VERSION ""

NS_ :

BS_:

BU_: Vector__XXX BSR CAA CAA00 CAA01 CGW CSR FCM FRD MAV

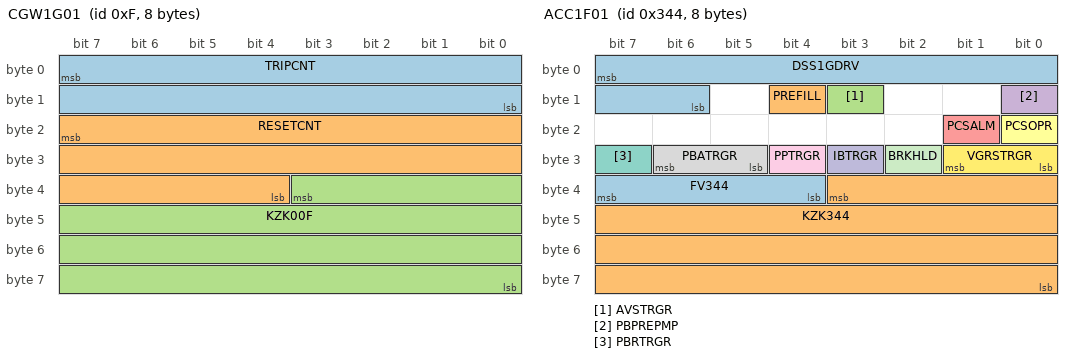
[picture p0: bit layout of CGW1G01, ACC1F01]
BO_ 15 CGW1G01: 8 Vector__XXX
  SG_ TRIPCNT   : 7|16@0+ (1,0) [0|0] "" Vector__XXX
  SG_ RESETCNT   : 23|20@0+ (1,0) [0|0] "" Vector__XXX
  SG_ KZK00F   : 35|28@0+ (1,0) [0|0] "" Vector__XXX

BO_ 836 ACC1F01: 8 FCM
  SG_ DSS1GDRV: 7|10@0- (0.1,0) [0|0] "m/s^2" CGW
  SG_ PREFILL: 12|1@0+ (1,0) [0|0] "" CGW
  SG_ AVSTRGR: 11|1@0+ (1,0) [0|0] "" CGW
  SG_ PBPREPMP: 8|1@0+ (1,0) [0|0] "" CGW
  SG_ PCSALM: 17|1@0+ (1,0) [0|0] "" CGW
  SG_ PCSOPR: 16|1@0+ (1,0) [0|0] "" CGW
  SG_ PBRTRGR: 31|1@0+ (1,0) [0|0] "" CGW
  SG_ PBATRGR: 30|2@0+ (1,0) [0|0] "" CGW
  SG_ PPTRGR: 28|1@0+ (1,0) [0|0] "" CGW
  SG_ IBTRGR: 27|1@0+ (1,0) [0|0] "" CGW
  SG_ BRKHLD: 26|1@0+ (1,0) [0|0] "" CGW
  SG_ VGRSTRGR: 25|2@0+ (1,0) [0|0] "" CGW
  SG_ FV344: 39|4@0+ (1,0) [0|0] "" CGW
  SG_ KZK344: 35|28@0+ (1,0) [0|0] "" CGW

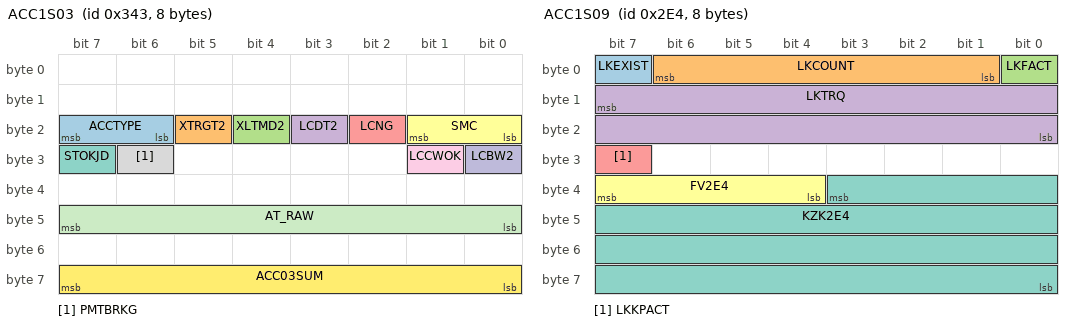
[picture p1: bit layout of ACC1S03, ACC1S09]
BO_ 835 ACC1S03: 8 FCM
  SG_ ACCTYPE: 23|2@0+ (1,0) [0|0] "" CGW
  SG_ XTRGT2: 21|1@0+ (1,0) [0|0] "" CGW
  SG_ XLTMD2: 20|1@0+ (1,0) [0|0] "" CGW
  SG_ LCDT2: 19|1@0+ (1,0) [0|0] "" CGW
  SG_ LCNG: 18|1@0+ (1,0) [0|0] "" CGW
  SG_ SMC: 17|2@0+ (1,0) [0|0] "" CGW
  SG_ STOKJD: 31|1@0+ (1,0) [0|0] "" CGW
  SG_ PMTBRKG: 30|1@0+ (1,0) [0|0] "" CGW
  SG_ LCCWOK: 25|1@0+ (1,0) [0|0] "" CGW
  SG_ LCBW2: 24|1@0+ (1,0) [0|0] "" CGW
  SG_ AT_RAW: 47|8@0- (0.05,0) [0|0] "m/s^2" CGW
  SG_ ACC03SUM: 63|8@0+ (1,0) [0|0] "" CGW

BO_ 740 ACC1S09: 8 FCM
  SG_ LKEXIST: 7|1@0+ (1,0) [0|0] "" CGW
  SG_ LKCOUNT: 6|6@0+ (1,0) [0|0] "" CGW
  SG_ LKFACT: 0|1@0+ (1,0) [0|0] "" CGW
  SG_ LKTRQ: 15|16@0- (0.01,0) [0|0] "Nm" CGW
  SG_ LKKPACT: 31|1@0+ (1,0) [0|0] "" CGW
  SG_ FV2E4: 39|4@0+ (1,0) [0|0] "" CGW
  SG_ KZK2E4: 35|28@0+ (1,0) [0|0] "" CGW

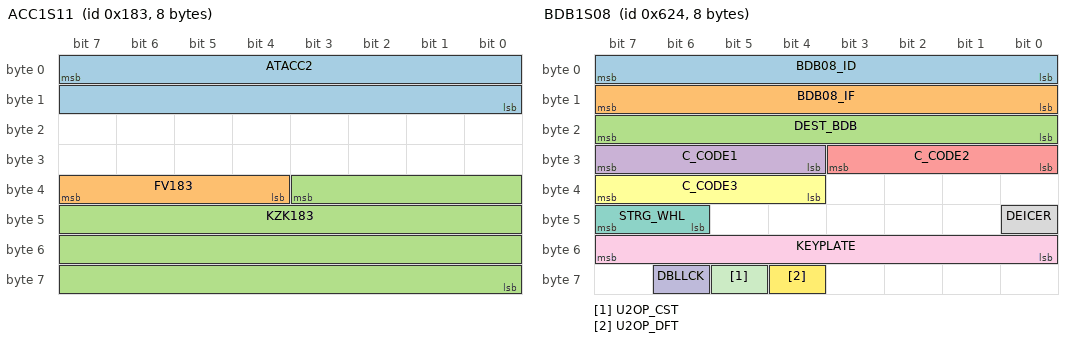
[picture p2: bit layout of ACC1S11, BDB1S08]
BO_ 387 ACC1S11: 8 FCM
  SG_ ATACC2: 7|16@0- (0.001,0) [0|0] "m/s^2" CGW
  SG_ FV183: 39|4@0+ (1,0) [0|0] "" CGW
  SG_ KZK183: 35|28@0+ (1,0) [0|0] "" CGW

BO_ 1572 BDB1S08: 8 CGW
  SG_ BDB08_ID: 7|8@0+ (1,0) [0|0] "" FCM
  SG_ BDB08_IF: 15|8@0+ (1,0) [0|0] "" FCM
  SG_ DEST_BDB: 23|8@0+ (1,0) [0|0] "" BSR,CAA,CAA00,CAA01,CSR,FCM,MAV
  SG_ C_CODE1: 31|4@0+ (1,0) [0|0] "" BSR,CAA,CAA00,CAA01,FCM,MAV
  SG_ C_CODE2: 27|4@0+ (1,0) [0|0] "" BSR,CAA,CAA00,CAA01,CSR,FCM,MAV
  SG_ C_CODE3: 39|4@0+ (1,0) [0|0] "" BSR,CAA,CAA00,CAA01,CSR,FCM,MAV
  SG_ STRG_WHL: 47|2@0+ (1,0) [0|0] "" CAA,CAA00,CAA01,CSR,FCM,MAV
  SG_ DEICER: 40|1@0+ (1,0) [0|0] "" Vector__XXX
  SG_ KEYPLATE: 55|8@0+ (1,0) [0|0] "" Vector__XXX
  SG_ DBLLCK: 62|1@0+ (1,0) [0|0] "" Vector__XXX
  SG_ U2OP_CST: 61|1@0+ (1,0) [0|0] "" Vector__XXX
  SG_ U2OP_DFT: 60|1@0+ (1,0) [0|0] "" Vector__XXX

BO_ 1014 BSR1S01: 8 BSR
  SG_ BSD_STAT: 7|3@0+ (1,0) [0|0] "" CGW
  SG_ RCTA_DIR: 4|3@0+ (1,0) [0|0] "" CAA,CAA00,CAA01,CGW,CSR,MAV
  SG_ BS4LDR: 1|1@0+ (1,0) [0|0] "" CGW,FCM
  SG_ BS4LDL: 0|1@0+ (1,0) [0|0] "" CGW,FCM
  SG_ BSD_SW: 15|1@0+ (1,0) [0|0] "" CGW
  SG_ RCTA_EQ: 14|1@0+ (1,0) [0|0] "" CGW,CSR
  SG_ RCTA_VOL: 13|2@0+ (1,0) [0|0] "" CGW,CSR
  SG_ RCTADISP: 11|1@0+ (1,0) [0|0] "" CAA,CAA00,CAA01,CGW,MAV
  SG_ CV4LDR: 10|1@0+ (1,0) [0|0] "" CGW,FCM
  SG_ RCTA_SW: 9|1@0+ (1,0) [0|0] "" CGW
  SG_ CV4LDL: 8|1@0+ (1,0) [0|0] "" CGW,FCM
  SG_ BSD_BUZ: 23|1@0+ (1,0) [0|0] "" CGW,CSR
  SG_ BSD_ILCR: 22|1@0+ (1,0) [0|0] "" CGW
  SG_ BSD_ILV: 21|3@0+ (1,0) [0|0] "" CGW
  SG_ BSD_ITCR: 18|1@0+ (1,0) [0|0] "" CGW
  SG_ BSD_ITV: 17|2@0+ (1,0) [0|0] "" CGW
  SG_ BSD_OMIL: 27|2@0+ (1,0) [0|0] "" CGW
  SG_ BSD_OMIR: 25|2@0+ (1,0) [0|0] "" CGW
  SG_ RCTASTAT: 39|3@0+ (1,0) [0|0] "" CGW
  SG_ BUZSTAT: 36|2@0+ (1,0) [0|0] "" CGW
  SG_ CAAICM: 34|1@0+ (1,0) [0|0] "" CGW
  SG_ RCTALAMP: 33|2@0+ (1,0) [0|0] "" CGW
  SG_ BSD_TTR: 47|1@0+ (1,0) [0|0] "" CGW
  SG_ BSDINDI: 46|1@0+ (1,0) [0|0] "" CGW
  SG_ RCTA_TTR: 45|1@0+ (1,0) [0|0] "" CGW
  SG_ BSD_SWR: 44|1@0+ (1,0) [0|0] "" CGW
  SG_ RCTA_SWR: 43|1@0+ (1,0) [0|0] "" CGW
  SG_ RCTA_BUZ: 42|1@0+ (1,0) [0|0] "" CGW,CSR
  SG_ RCTA_BCR: 41|1@0+ (1,0) [0|0] "" CGW

BO_ 870 DS11D71: 7 FCM
  SG_ TGT_ETTC: 7|6@0+ (0.1,0) [0|0] "s" CGW
  SG_ XREQPBR: 1|1@0+ (1,0) [0|0] "" CGW
  SG_ XREQPREF: 0|1@0+ (1,0) [0|0] "" CGW
  SG_ TGT_OBJT: 15|4@0+ (1,0) [0|0] "" CGW
  SG_ XREQALM: 11|2@0+ (1,0) [0|0] "" CGW
  SG_ XREQPBA: 9|2@0+ (1,0) [0|0] "" CGW
  SG_ TGT_VGAP: 23|9@0- (0.14,-21.7) [0|0] "m/s" CGW
  SG_ TGT_DIST: 30|7@0+ (0.79,0) [0|0] "m" CGW
  SG_ TGT_NUMB: 39|5@0+ (1,1) [0|0] "" CGW
  SG_ XREQABK: 34|1@0+ (1,0) [0|0] "" CGW
  SG_ XREQFPB: 33|1@0+ (1,0) [0|0] "" CGW
  SG_ XREQPB: 32|1@0+ (1,0) [0|0] "" CGW
  SG_ TGT_POSX: 47|5@0- (0.32,0) [0|0] "m" CGW
  SG_ XREQPSB: 42|1@0+ (1,0) [0|0] "" CGW
  SG_ XPCSRDY: 41|1@0+ (1,0) [0|0] "" CGW
  SG_ TGT_TTCT: 40|1@0+ (1,0) [0|0] "" CGW
  SG_ ALLPCSF: 55|1@0+ (1,0) [0|0] "" CGW
  SG_ TGT_LSPD: 54|7@0- (0.2,0) [0|0] "m/s" CGW

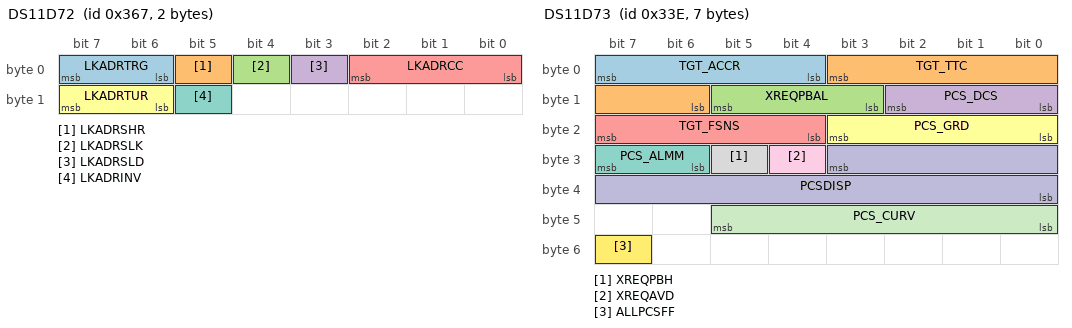
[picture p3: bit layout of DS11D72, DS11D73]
BO_ 871 DS11D72: 2 FCM
  SG_ LKADRTRG: 7|2@0+ (1,0) [0|0] "" CGW
  SG_ LKADRSHR: 5|1@0+ (1,0) [0|0] "" CGW
  SG_ LKADRSLK: 4|1@0+ (1,0) [0|0] "" CGW
  SG_ LKADRSLD: 3|1@0+ (1,0) [0|0] "" CGW
  SG_ LKADRCC: 2|3@0+ (1,0) [0|0] "" CGW
  SG_ LKADRTUR: 15|2@0+ (1,0) [0|0] "" CGW
  SG_ LKADRINV: 13|1@0+ (1,0) [0|0] "" CGW

BO_ 830 DS11D73: 7 FCM
  SG_ TGT_ACCR: 7|4@0- (1,0) [0|0] "m/s2" CGW
  SG_ TGT_TTC: 3|6@0+ (0.1,0) [0|0] "s" CGW
  SG_ XREQPBAL: 13|3@0+ (1,0) [0|0] "" CGW
  SG_ PCS_DCS: 10|3@0+ (1,0) [0|0] "" CGW
  SG_ TGT_FSNS: 23|4@0+ (1,0) [0|0] "" CGW
  SG_ PCS_GRD: 19|4@0+ (1,0) [0|0] "" CGW
  SG_ PCS_ALMM: 31|2@0+ (1,0) [0|0] "" CGW
  SG_ XREQPBH: 29|1@0+ (1,0) [0|0] "" CGW
  SG_ XREQAVD: 28|1@0+ (1,0) [0|0] "" CGW
  SG_ PCSDISP: 27|12@0+ (1,0) [0|0] "" CGW
  SG_ PCS_CURV: 45|6@0- (200,0) [0|0] "m" CGW
  SG_ ALLPCSFF: 55|1@0+ (1,0) [0|0] "" CGW

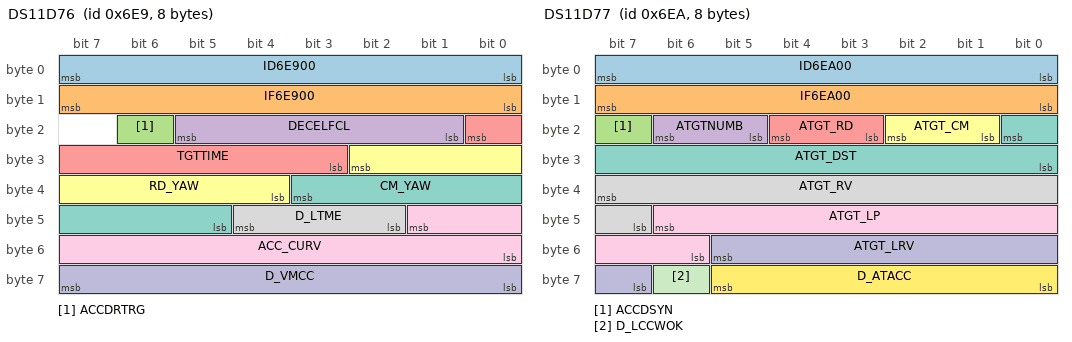
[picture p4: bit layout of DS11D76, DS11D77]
BO_ 1769 DS11D76: 8 FCM
  SG_ ID6E900: 7|8@0+ (1,0) [0|0] "" CGW
  SG_ IF6E900: 15|8@0+ (1,0) [0|0] "" CGW
  SG_ ACCDRTRG: 22|1@0+ (1,0) [0|0] "" CGW
  SG_ DECELFCL: 21|5@0+ (0.2,0) [0|0] "m/s^2" CGW
  SG_ TGTTIME: 16|6@0+ (0.2,0) [0|0] "s" CGW
  SG_ RD_YAW: 26|7@0- (0.1,0) [0|0] "deg" CGW
  SG_ CM_YAW: 35|7@0- (0.1,0) [0|0] "deg" CGW
  SG_ D_LTME: 44|3@0+ (1,0) [0|0] "" CGW
  SG_ ACC_CURV: 41|10@0- (50,0) [0|0] "m" CGW
  SG_ D_VMCC: 63|8@0+ (1,0) [0|0] "km/h" CGW

BO_ 1770 DS11D77: 8 FCM
  SG_ ID6EA00: 7|8@0+ (1,0) [0|0] "" CGW
  SG_ IF6EA00: 15|8@0+ (1,0) [0|0] "" CGW
  SG_ ACCDSYN: 23|1@0+ (1,0) [0|0] "" CGW
  SG_ ATGTNUMB: 22|2@0+ (1,0) [0|0] "" CGW
  SG_ ATGT_RD: 20|2@0+ (1,0) [0|0] "" CGW
  SG_ ATGT_CM: 18|2@0+ (1,0) [0|0] "" CGW
  SG_ ATGT_DST: 16|9@0+ (1,0) [0|0] "m" CGW
  SG_ ATGT_RV: 39|9@0- (0.3,0) [0|0] "m/s" CGW
  SG_ ATGT_LP: 46|9@0- (0.2,0) [0|0] "m" CGW
  SG_ ATGT_LRV: 53|7@0- (0.2,0) [0|0] "m/s" CGW
  SG_ D_LCCWOK: 62|1@0+ (1,0) [0|0] "" CGW
  SG_ D_ATACC: 61|6@0- (0.2,0) [0|0] "m/s^2" CGW

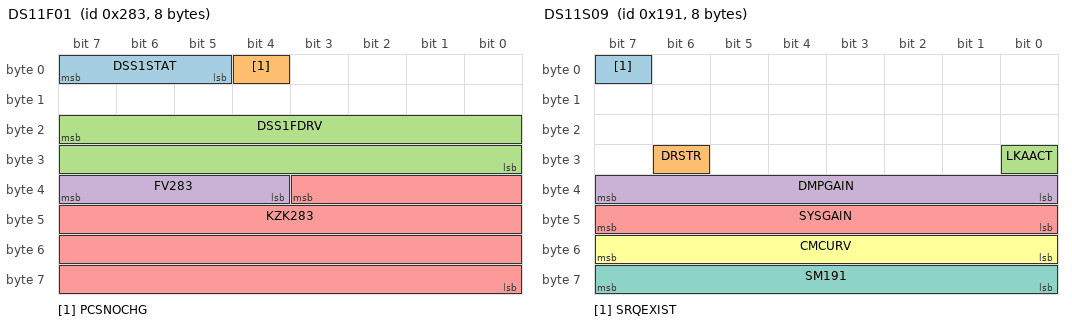
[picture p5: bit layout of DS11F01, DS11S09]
BO_ 643 DS11F01: 8 FCM
  SG_ DSS1STAT: 7|3@0+ (1,0) [0|0] "" CGW
  SG_ PCSNOCHG: 4|1@0+ (1,0) [0|0] "" CGW
  SG_ DSS1FDRV: 23|16@0- (2,0) [0|0] "N" CGW
  SG_ FV283: 39|4@0+ (1,0) [0|0] "" CGW
  SG_ KZK283: 35|28@0+ (1,0) [0|0] "" CGW

BO_ 401 DS11S09: 8 FCM
  SG_ SRQEXIST: 7|1@0+ (1,0) [0|0] "" CGW
  SG_ DRSTR: 30|1@0+ (1,0) [0|0] "" CGW
  SG_ LKAACT: 24|1@0+ (1,0) [0|0] "" CGW
  SG_ DMPGAIN: 39|8@0+ (0.01,0) [0|0] "" CGW
  SG_ SYSGAIN: 47|8@0+ (0.01,0) [0|0] "" CGW
  SG_ CMCURV: 55|8@0- (0.0001,0) [0|0] "1/m" CGW
  SG_ SM191: 63|8@0+ (1,0) [0|0] "" CGW

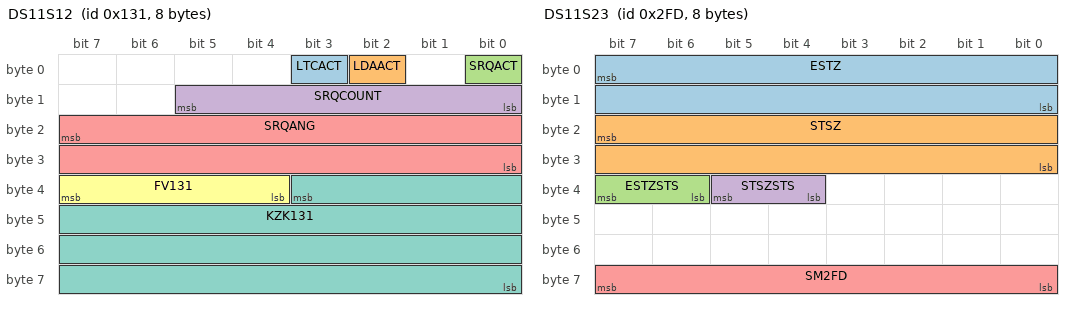
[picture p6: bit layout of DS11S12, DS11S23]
BO_ 305 DS11S12: 8 FCM
  SG_ LTCACT: 3|1@0+ (1,0) [0|0] "" CGW
  SG_ LDAACT: 2|1@0+ (1,0) [0|0] "" CGW
  SG_ SRQACT: 0|1@0+ (1,0) [0|0] "" CGW
  SG_ SRQCOUNT: 13|6@0+ (1,0) [0|0] "" CGW
  SG_ SRQANG: 23|16@0- (0.001,0) [0|0] "rad" CGW
  SG_ FV131: 39|4@0+ (1,0) [0|0] "" CGW
  SG_ KZK131: 35|28@0+ (1,0) [0|0] "" CGW

BO_ 765 DS11S23: 8 FCM
  SG_ ESTZ: 7|16@0- (0.001,0) [0|0] "rad" CGW
  SG_ STSZ: 23|16@0- (0.001,0) [0|0] "rad" CGW
  SG_ ESTZSTS: 39|2@0+ (1,0) [0|0] "" CGW
  SG_ STSZSTS: 37|2@0+ (1,0) [0|0] "" CGW
  SG_ SM2FD: 63|8@0+ (1,0) [0|0] "" CGW

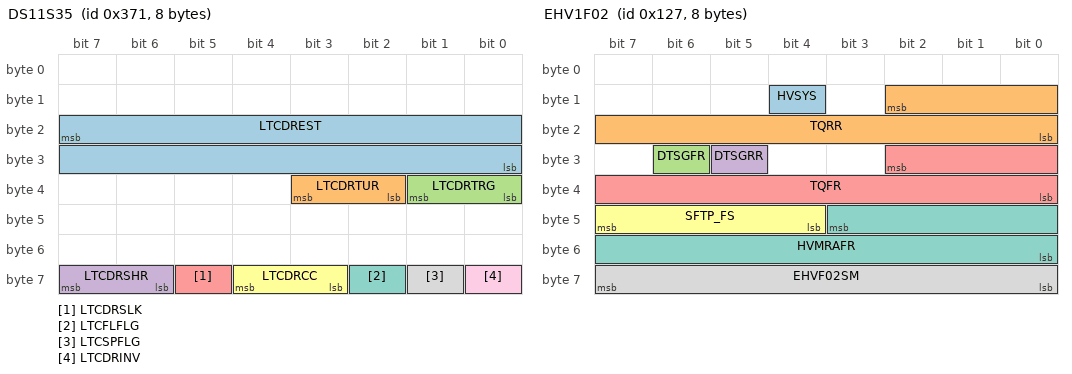
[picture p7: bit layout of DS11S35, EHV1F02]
BO_ 881 DS11S35: 8 FCM
  SG_ LTCDREST: 23|16@0- (0.001,0) [0|0] "rad" CGW
  SG_ LTCDRTUR: 35|2@0+ (1,0) [0|0] "" CGW
  SG_ LTCDRTRG: 33|2@0+ (1,0) [0|0] "" CGW
  SG_ LTCDRSHR: 63|2@0+ (1,0) [0|0] "" CGW
  SG_ LTCDRSLK: 61|1@0+ (1,0) [0|0] "" CGW
  SG_ LTCDRCC: 60|2@0+ (1,0) [0|0] "" CGW
  SG_ LTCFLFLG: 58|1@0+ (1,0) [0|0] "" CGW
  SG_ LTCSPFLG: 57|1@0+ (1,0) [0|0] "" CGW
  SG_ LTCDRINV: 56|1@0+ (1,0) [0|0] "" CGW

BO_ 1041 DS12F02: 8 FCM
  SG_ PCSINDI: 7|2@0+ (1,0) [0|0] "" CGW
  SG_ PCSWM: 5|2@0+ (1,0) [0|0] "" CGW
  SG_ PCSFCT: 3|1@0+ (1,0) [0|0] "" CGW
  SG_ PCSTUCT: 2|1@0+ (1,0) [0|0] "" CGW
  SG_ DS1LCCK: 1|2@0+ (1,0) [0|0] "" CGW
  SG_ PBTUCT: 14|1@0+ (1,0) [0|0] "" CGW
  SG_ PCSEXIST: 13|1@0+ (1,0) [0|0] "" CGW
  SG_ PCSWDUCT: 11|1@0+ (1,0) [0|0] "" CGW
  SG_ PCSMTBZ2: 27|4@0+ (1,0) [0|0] "" CGW
  SG_ PCSDSRF: 36|1@0+ (1,0) [0|0] "" CGW
  SG_ PCSTEMP: 35|1@0+ (1,0) [0|0] "" CGW
  SG_ PCSDUST: 34|1@0+ (1,0) [0|0] "" CGW
  SG_ PCSLCCK: 33|2@0+ (1,0) [0|0] "" CGW
  SG_ PCTEMP2: 42|1@0+ (1,0) [0|0] "" CGW
  SG_ PCSDUST2: 41|1@0+ (1,0) [0|0] "" CGW
  SG_ PCSOFFS: 40|1@0+ (1,0) [0|0] "" CGW
  SG_ PCSWDS: 55|2@0+ (1,0) [0|0] "" CGW
  SG_ FRDADJ: 53|3@0+ (1,0) [0|0] "" CGW
  SG_ TSS_TS: 49|1@0+ (1,0) [0|0] "" CGW

BO_ 1042 DS12F03: 8 FCM
  SG_ LKAINDI: 7|2@0+ (1,0) [0|0] "" CGW
  SG_ LKAWLSL: 5|2@0+ (1,0) [0|0] "" CGW
  SG_ LKAWLSR: 3|2@0+ (1,0) [0|0] "" CGW
  SG_ LKAHS: 1|2@0+ (1,0) [0|0] "" CGW
  SG_ LKAFCT: 15|1@0+ (1,0) [0|0] "" CGW
  SG_ LKATUCT: 14|1@0+ (1,0) [0|0] "" CGW
  SG_ LKACAMT: 13|1@0+ (1,0) [0|0] "" CGW
  SG_ LKACB: 12|1@0+ (1,0) [0|0] "" CGW
  SG_ LDWEXIST: 10|1@0+ (1,0) [0|0] "" CGW
  SG_ LKAHFCT: 9|2@0+ (1,0) [0|0] "" CGW
  SG_ LKASPCND: 23|3@0+ (1,0) [0|0] "" CGW
  SG_ LKAMDCS: 20|2@0+ (1,0) [0|0] "" CGW
  SG_ LKAWTCS: 18|2@0+ (1,0) [0|0] "" CGW
  SG_ LKASAUT: 16|1@0+ (1,0) [0|0] "" CGW
  SG_ LKAMDT: 31|2@0+ (1,0) [0|0] "" CGW
  SG_ LTCCNFLV: 29|2@0+ (1,0) [0|0] "" CGW
  SG_ FLWMD2: 39|2@0+ (1,0) [0|0] "" CGW
  SG_ LDOFINDI: 37|1@0+ (1,0) [0|0] "" CGW
  SG_ LTCEXST2: 36|1@0+ (1,0) [0|0] "" CGW
  SG_ LDWBZ: 32|1@0+ (1,0) [0|0] "" CGW
  SG_ LDAFCVB: 47|1@0+ (1,0) [0|0] "" CGW
  SG_ SWSSENSD: 45|2@0+ (1,0) [0|0] "" CGW
  SG_ SWSSWD: 43|1@0+ (1,0) [0|0] "" CGW
  SG_ LDACD: 42|3@0+ (1,0) [0|0] "" CGW
  SG_ SWSRAD: 55|2@0+ (1,0) [0|0] "" CGW
  SG_ SWSBUZ: 50|2@0+ (1,0) [0|0] "" CGW
  SG_ LKAEXIST: 48|1@0+ (1,0) [0|0] "" CGW
  SG_ LKACTCD: 60|1@0+ (1,0) [0|0] "" CGW
  SG_ LDAWRNC: 59|1@0+ (1,0) [0|0] "" CGW
  SG_ SCEXIST: 57|1@0+ (1,0) [0|0] "" CGW
  SG_ VIBEXIST: 56|1@0+ (1,0) [0|0] "" CGW

BO_ 295 EHV1F02: 8 CGW
  SG_ HVSYS: 12|1@0+ (1,0) [0|0] "" CSR
  SG_ TQRR: 10|11@0- (8,0) [0|0] "Nm" Vector__XXX
  SG_ DTSGFR: 30|1@0+ (1,0) [0|0] "" Vector__XXX
  SG_ DTSGRR: 29|1@0+ (1,0) [0|0] "" Vector__XXX
  SG_ TQFR: 26|11@0- (8,0) [0|0] "Nm" Vector__XXX
  SG_ SFTP_FS: 47|4@0+ (1,0) [0|0] "" CSR
  SG_ HVMRAFR: 43|12@0+ (0.3515625,0) [0|0] "deg" Vector__XXX
  SG_ EHVF02SM: 63|8@0+ (1,0) [0|0] "" CSR

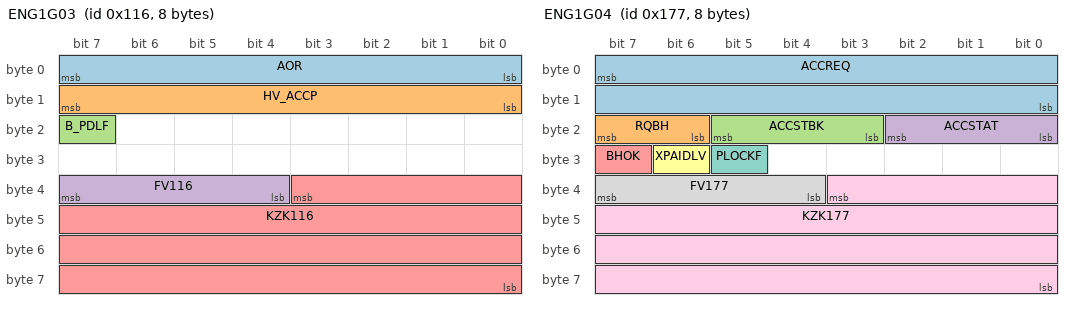
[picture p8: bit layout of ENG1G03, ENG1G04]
BO_ 278 ENG1G03: 8 CGW
  SG_ AOR: 7|8@0+ (0.5,0) [0|0] "%" Vector__XXX
  SG_ HV_ACCP: 15|8@0+ (0.5,0) [0|0] "%" CSR,FCM
  SG_ B_PDLF: 23|1@0+ (1,0) [0|0] "" FCM
  SG_ FV116: 39|4@0+ (1,0) [0|0] "" FCM
  SG_ KZK116: 35|28@0+ (1,0) [0|0] "" FCM

BO_ 375 ENG1G04: 8 CGW
  SG_ ACCREQ: 7|16@0- (0.0009765625,0) [0|0] "m/s^2" Vector__XXX
  SG_ RQBH: 23|2@0+ (1,0) [0|0] "" Vector__XXX
  SG_ ACCSTBK: 21|3@0+ (1,0) [0|0] "" Vector__XXX
  SG_ ACCSTAT: 18|3@0+ (1,0) [0|0] "" Vector__XXX
  SG_ BHOK: 31|1@0+ (1,0) [0|0] "" Vector__XXX
  SG_ XPAIDLV: 30|1@0+ (1,0) [0|0] "" CSR,FCM
  SG_ PLOCKF: 29|1@0+ (1,0) [0|0] "" Vector__XXX
  SG_ FV177: 39|4@0+ (1,0) [0|0] "" Vector__XXX
  SG_ KZK177: 35|28@0+ (1,0) [0|0] "" Vector__XXX

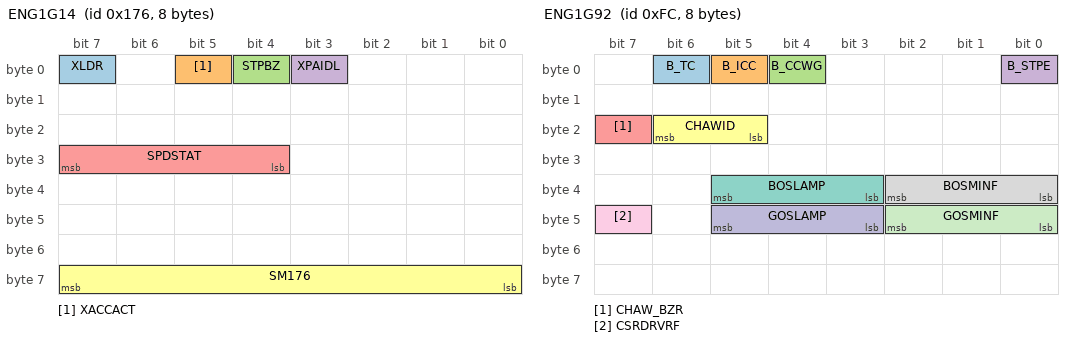
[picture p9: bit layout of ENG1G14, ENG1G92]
BO_ 374 ENG1G14: 8 CGW
  SG_ XLDR: 7|1@0+ (1,0) [0|0] "" FCM
  SG_ XACCACT: 5|1@0+ (1,0) [0|0] "" FCM
  SG_ STPBZ: 4|1@0+ (1,0) [0|0] "" FCM
  SG_ XPAIDL: 3|1@0+ (1,0) [0|0] "" FCM
  SG_ SPDSTAT: 31|4@0+ (1,0) [0|0] "�|" FCM
  SG_ SM176: 63|8@0+ (1,0) [0|0] "" FCM

BO_ 252 ENG1G92: 8 CGW
  SG_ B_TC: 6|1@0+ (1,0) [0|0] "" Vector__XXX
  SG_ B_ICC: 5|1@0+ (1,0) [0|0] "" Vector__XXX
  SG_ B_CCWG: 4|1@0+ (1,0) [0|0] "" Vector__XXX
  SG_ B_STPE: 0|1@0+ (1,0) [0|0] "" Vector__XXX
  SG_ CHAW_BZR: 23|1@0+ (1,0) [0|0] "" Vector__XXX
  SG_ CHAWID: 22|2@0+ (1,0) [0|0] "" Vector__XXX
  SG_ BOSLAMP: 37|3@0+ (1,0) [0|0] "" Vector__XXX
  SG_ BOSMINF: 34|3@0+ (1,0) [0|0] "" Vector__XXX
  SG_ CSRDRVRF: 47|1@0+ (1,0) [0|0] "" CSR
  SG_ GOSLAMP: 45|3@0+ (1,0) [0|0] "" FCM
  SG_ GOSMINF: 42|3@0+ (1,0) [0|0] "" FCM

BO_ 921 ENG1S95: 8 CGW
  SG_ ACCBZR: 7|3@0+ (1,0) [0|0] "" Vector__XXX
  SG_ B_SPU2: 4|1@0+ (1,0) [0|0] "" Vector__XXX
  SG_ ACASID1: 3|4@0+ (1,0) [0|0] "" Vector__XXX
  SG_ ACASID2: 15|8@0+ (1,0) [0|0] "" Vector__XXX
  SG_ RACMSDSP: 23|2@0+ (1,0) [0|0] "" Vector__XXX
  SG_ RACACOPR: 21|1@0+ (1,0) [0|0] "" Vector__XXX
  SG_ RACONDSP: 20|1@0+ (1,0) [0|0] "" Vector__XXX
  SG_ ASLBZR: 19|2@0+ (1,0) [0|0] "" Vector__XXX
  SG_ ACCOVSPD: 17|2@0+ (1,0) [0|0] "" Vector__XXX
  SG_ B_LSP2: 31|8@0+ (1,0) [0|0] "km/h�Emph" Vector__XXX
  SG_ B_ASLSP2: 39|8@0+ (1,0) [0|0] "km/h�Emph" Vector__XXX
  SG_ CACCTRN: 47|1@0+ (1,0) [0|0] "" Vector__XXX
  SG_ CACCINF: 46|1@0+ (1,0) [0|0] "" Vector__XXX
  SG_ CACCFR2: 45|1@0+ (1,0) [0|0] "" Vector__XXX
  SG_ CACCFR1: 44|1@0+ (1,0) [0|0] "" Vector__XXX
  SG_ CACCFLD: 43|1@0+ (1,0) [0|0] "" Vector__XXX
  SG_ CACCCM3: 42|1@0+ (1,0) [0|0] "" Vector__XXX
  SG_ CACCCM2: 41|1@0+ (1,0) [0|0] "" Vector__XXX
  SG_ CACCCM1: 40|1@0+ (1,0) [0|0] "" Vector__XXX
  SG_ ASLRNG: 55|1@0+ (1,0) [0|0] "" FCM
  SG_ RACCSTM2: 52|1@0+ (1,0) [0|0] "" Vector__XXX
  SG_ RACCSTM1: 51|2@0+ (1,0) [0|0] "" Vector__XXX
  SG_ RACEQPD: 49|1@0+ (1,0) [0|0] "" Vector__XXX
  SG_ RACID: 48|1@0+ (1,0) [0|0] "" Vector__XXX
  SG_ RACSPDOP: 63|8@0+ (1,0) [0|0] "km/h�Emph" Vector__XXX

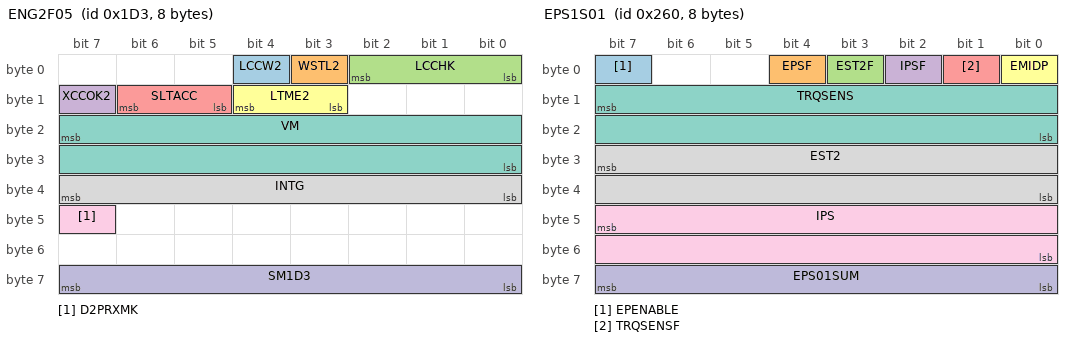
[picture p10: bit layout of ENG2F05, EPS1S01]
BO_ 467 ENG2F05: 8 CGW
  SG_ LCCW2: 4|1@0+ (1,0) [0|0] "" FCM
  SG_ WSTL2: 3|1@0+ (1,0) [0|0] "" FCM
  SG_ LCCHK: 2|3@0+ (1,0) [0|0] "" FCM
  SG_ XCCOK2: 15|1@0+ (1,0) [0|0] "" FCM
  SG_ SLTACC: 14|2@0+ (1,0) [0|0] "" FCM
  SG_ LTME2: 12|2@0+ (1,0) [0|0] "" FCM
  SG_ VM: 23|16@0+ (0.00390625,0) [0|0] "km/h" FCM
  SG_ INTG: 39|8@0- (0.04,0) [0|0] "m/s^2" FCM
  SG_ D2PRXMK: 47|1@0+ (1,0) [0|0] "" Vector__XXX
  SG_ SM1D3: 63|8@0+ (1,0) [0|0] "" FCM

BO_ 608 EPS1S01: 8 CGW
  SG_ EPENABLE: 7|1@0+ (1,0) [0|0] "" Vector__XXX
  SG_ EPSF: 4|1@0+ (1,0) [0|0] "" Vector__XXX
  SG_ EST2F: 3|1@0+ (1,0) [0|0] "" FCM
  SG_ IPSF: 2|1@0+ (1,0) [0|0] "" FCM
  SG_ TRQSENSF: 1|1@0+ (1,0) [0|0] "" FCM
  SG_ EMIDP: 0|1@0+ (1,0) [0|0] "" Vector__XXX
  SG_ TRQSENS: 15|16@0- (0.01,0) [0|0] "Nm" FCM
  SG_ EST2: 31|16@0- (0.001,0) [0|0] "rad" FCM
  SG_ IPS: 47|16@0- (0.01,0) [0|0] "A" FCM
  SG_ EPS01SUM: 63|8@0+ (1,0) [0|0] "" FCM

BO_ 610 EPS1S02: 8 CGW
  SG_ EPSFAIL: 7|1@0+ (1,0) [0|0] "" Vector__XXX
  SG_ EPSSPD: 6|1@0+ (1,0) [0|0] "" Vector__XXX
  SG_ EPSFCM: 5|1@0+ (1,0) [0|0] "" Vector__XXX
  SG_ EPSSTS0: 2|1@0+ (1,0) [0|0] "" Vector__XXX
  SG_ EPSACT: 1|1@0+ (1,0) [0|0] "" Vector__XXX
  SG_ EPSSYS: 0|1@0+ (1,0) [0|0] "" Vector__XXX
  SG_ EPSFANG: 15|1@0+ (1,0) [0|0] "" FCM
  SG_ EPSBKUP2: 14|1@0+ (1,0) [0|0] "" FCM
  SG_ EPSACT3: 13|1@0+ (1,0) [0|0] "" FCM
  SG_ EPSFCM3: 12|1@0+ (1,0) [0|0] "" FCM
  SG_ EPSSYS3: 11|1@0+ (1,0) [0|0] "" FCM
  SG_ EPSTG: 31|1@0+ (1,0) [0|0] "" Vector__XXX
  SG_ EPSCD: 30|1@0+ (1,0) [0|0] "" Vector__XXX
  SG_ EPSFTRQ: 29|1@0+ (1,0) [0|0] "" FCM
  SG_ EPSBKUP: 28|1@0+ (1,0) [0|0] "" FCM
  SG_ EPSACT2: 27|1@0+ (1,0) [0|0] "" FCM
  SG_ EPSFCM2: 26|1@0+ (1,0) [0|0] "" FCM
  SG_ EPSSYS2: 25|1@0+ (1,0) [0|0] "" FCM
  SG_ EPSBRUSH: 24|1@0+ (1,0) [0|0] "" Vector__XXX
  SG_ DGRDF: 39|1@0+ (1,0) [0|0] "" FCM
  SG_ GRDF: 38|1@0+ (1,0) [0|0] "" FCM
  SG_ ESTZ2E: 37|1@0+ (1,0) [0|0] "" FCM
  SG_ ESTZUDS: 36|2@0+ (1,0) [0|0] "" FCM
  SG_ EPSTEMP1: 47|8@0+ (0.5,70) [0|0] "��" Vector__XXX
  SG_ EPSTEMP2: 55|8@0+ (0.5,70) [0|0] "��" Vector__XXX
  SG_ EPS02SUM: 63|8@0+ (1,0) [0|0] "" FCM

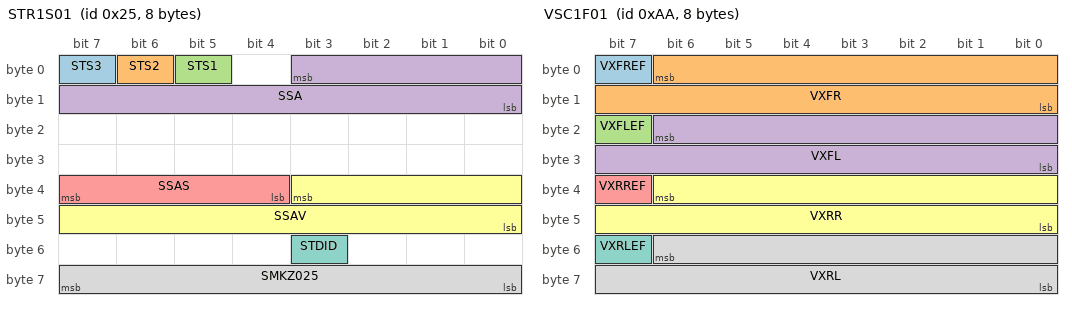
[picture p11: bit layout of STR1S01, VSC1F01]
BO_ 37 STR1S01: 8 CGW
  SG_ STS3: 7|1@0+ (1,0) [0|0] "" BSR,CAA,CAA00,CAA01,CSR,FCM,MAV
  SG_ STS2: 6|1@0+ (1,0) [0|0] "" CSR,FCM
  SG_ STS1: 5|1@0+ (1,0) [0|0] "" BSR,CAA,CAA00,CAA01,CSR,FCM,MAV
  SG_ SSA: 3|12@0- (1.5,0) [0|0] "deg" BSR,CAA,CAA00,CAA01,CSR,FCM,MAV
  SG_ SSAS: 39|4@0- (0.1,0) [0|0] "deg" FCM
  SG_ SSAV: 35|12@0- (1,0) [0|0] "deg/s" FCM
  SG_ STDID: 51|1@0+ (1,0) [0|0] "" Vector__XXX
  SG_ SMKZ025: 63|8@0+ (1,0) [0|0] "" CSR,FCM

BO_ 170 VSC1F01: 8 CGW
  SG_ VXFREF: 7|1@0+ (1,0) [0|0] "" BSR,CAA,CAA01,CSR,FCM
  SG_ VXFR: 6|15@0+ (0.01,-67.67) [0|0] "km/h" BSR,CSR,FCM
  SG_ VXFLEF: 23|1@0+ (1,0) [0|0] "" BSR,CAA,CAA01,CSR,FCM
  SG_ VXFL: 22|15@0+ (0.01,-67.67) [0|0] "km/h" BSR,CSR,FCM
  SG_ VXRREF: 39|1@0+ (1,0) [0|0] "" BSR,CAA,CAA01,CSR,FCM
  SG_ VXRR: 38|15@0+ (0.01,-67.67) [0|0] "km/h" BSR,CSR,FCM
  SG_ VXRLEF: 55|1@0+ (1,0) [0|0] "" BSR,CAA,CAA01,CSR,FCM
  SG_ VXRL: 54|15@0+ (0.01,-67.67) [0|0] "km/h" BSR,CSR,FCM

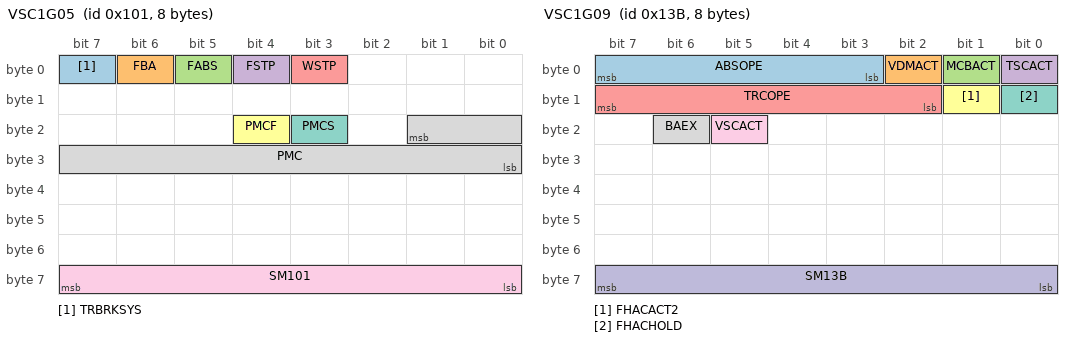
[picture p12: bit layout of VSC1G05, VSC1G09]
BO_ 257 VSC1G05: 8 CGW
  SG_ TRBRKSYS: 7|1@0+ (1,0) [0|0] "" Vector__XXX
  SG_ FBA: 6|1@0+ (1,0) [0|0] "" CSR,FCM
  SG_ FABS: 5|1@0+ (1,0) [0|0] "" CSR,FCM
  SG_ FSTP: 4|1@0+ (1,0) [0|0] "" CSR
  SG_ WSTP: 3|1@0+ (1,0) [0|0] "" CSR,FCM
  SG_ PMCF: 20|1@0+ (1,0) [0|0] "" CSR,FCM
  SG_ PMCS: 19|1@0+ (1,0) [0|0] "" CSR,FCM
  SG_ PMC: 17|10@0+ (0.02,0) [0|0] "Mpa" CSR,FCM
  SG_ SM101: 63|8@0+ (1,0) [0|0] "" CSR,FCM

BO_ 417 VSC1G07: 8 CGW
  SG_ FBKRLY: 6|1@0+ (1,0) [0|0] "" CSR,FCM
  SG_ FVSCM: 4|1@0+ (1,0) [0|0] "" Vector__XXX
  SG_ FVSCSFT: 3|1@0+ (1,0) [0|0] "" FCM
  SG_ CCS: 2|1@0+ (1,0) [0|0] "" Vector__XXX
  SG_ TSVSC: 1|1@0+ (1,0) [0|0] "" FCM
  SG_ FVSCL: 0|1@0+ (1,0) [0|0] "" Vector__XXX
  SG_ BRSTOP: 9|1@0+ (1,0) [0|0] "" Vector__XXX
  SG_ BRKON: 8|1@0+ (1,0) [0|0] "" FCM
  SG_ ASLP: 23|8@0- (1,0) [0|0] "deg" Vector__XXX
  SG_ BRKABT3: 26|1@0+ (1,0) [0|0] "" CSR,FCM
  SG_ BRKABT2: 25|1@0+ (1,0) [0|0] "" CSR
  SG_ BRKABT1: 24|1@0+ (1,0) [0|0] "" CSR
  SG_ GVC: 39|8@0- (0.04,0) [0|0] "m/s^2" FCM
  SG_ XGVCINV: 43|1@0+ (1,0) [0|0] "" Vector__XXX
  SG_ CSRICM: 40|1@0+ (1,0) [0|0] "" CSR
  SG_ S07CNT: 52|1@0+ (1,0) [0|0] "" Vector__XXX
  SG_ PCSBRSTA: 50|2@0+ (1,0) [0|0] "" FCM
  SG_ SM1A1: 63|8@0+ (1,0) [0|0] "" CSR,FCM

BO_ 315 VSC1G09: 8 CGW
  SG_ ABSOPE: 7|5@0+ (1,0) [0|0] "" FCM,MAV
  SG_ VDMACT: 2|1@0+ (1,0) [0|0] "" FCM
  SG_ MCBACT: 1|1@0+ (1,0) [0|0] "" Vector__XXX
  SG_ TSCACT: 0|1@0+ (1,0) [0|0] "" Vector__XXX
  SG_ TRCOPE: 15|6@0+ (1,0) [0|0] "" FCM
  SG_ FHACACT2: 9|1@0+ (1,0) [0|0] "" Vector__XXX
  SG_ FHACHOLD: 8|1@0+ (1,0) [0|0] "" Vector__XXX
  SG_ BAEX: 22|1@0+ (1,0) [0|0] "" Vector__XXX
  SG_ VSCACT: 21|1@0+ (1,0) [0|0] "" FCM
  SG_ SM13B: 63|8@0+ (1,0) [0|0] "" FCM

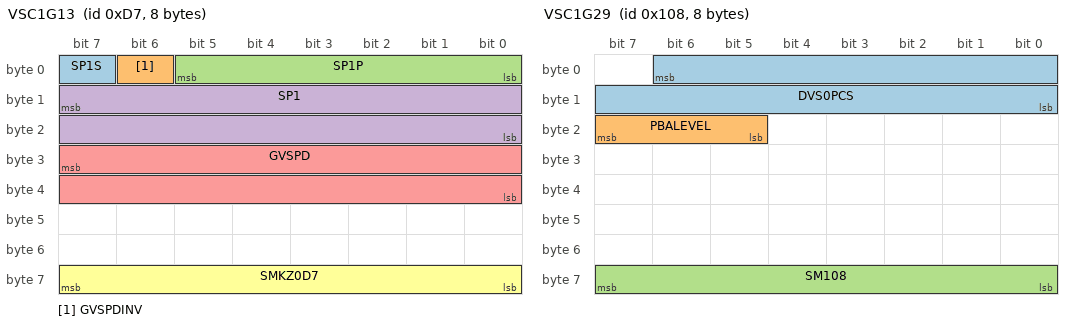
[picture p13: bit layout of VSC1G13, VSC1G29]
BO_ 215 VSC1G13: 8 CGW
  SG_ SP1S: 7|1@0+ (1,0) [0|0] "" BSR,FCM,MAV
  SG_ GVSPDINV: 6|1@0+ (1,0) [0|0] "" Vector__XXX
  SG_ SP1P: 5|6@0+ (1,0) [0|0] "" FCM
  SG_ SP1: 15|16@0+ (0.01,0) [0|0] "km/h" FCM,MAV
  SG_ GVSPD: 31|16@0+ (0.01,0) [0|0] "km/h" Vector__XXX
  SG_ SMKZ0D7: 63|8@0+ (1,0) [0|0] "" FCM

BO_ 264 VSC1G29: 8 CGW
  SG_ DVS0PCS: 6|15@0- (0.001,0) [0|0] "m/s^2" FCM
  SG_ PBALEVEL: 23|3@0+ (1,0) [0|0] "" FCM
  SG_ SM108: 63|8@0+ (1,0) [0|0] "" FCM

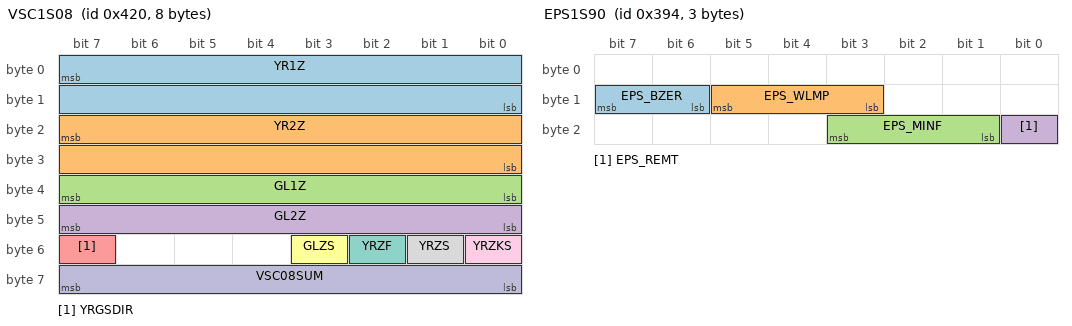
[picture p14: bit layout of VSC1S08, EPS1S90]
BO_ 1056 VSC1S08: 8 CGW
  SG_ YR1Z: 7|16@0- (5.32309722222222E-04,0) [0|0] "rad/s" Vector__XXX
  SG_ YR2Z: 23|16@0- (5.32309722222222E-04,0) [0|0] "rad/s" Vector__XXX
  SG_ GL1Z: 39|8@0- (0.0359,0) [0|0] "m/s^2" Vector__XXX
  SG_ GL2Z: 47|8@0- (0.0359,0) [0|0] "m/s^2" Vector__XXX
  SG_ YRGSDIR: 55|1@0+ (1,0) [0|0] "" Vector__XXX
  SG_ GLZS: 51|1@0+ (1,0) [0|0] "" Vector__XXX
  SG_ YRZF: 50|1@0+ (1,0) [0|0] "" FCM
  SG_ YRZS: 49|1@0+ (1,0) [0|0] "" Vector__XXX
  SG_ YRZKS: 48|1@0+ (1,0) [0|0] "" Vector__XXX
  SG_ VSC08SUM: 63|8@0+ (1,0) [0|0] "" Vector__XXX

BO_ 916 EPS1S90: 3 Vector__XXX
  SG_ EPS_BZER   : 15|2@0+ (1,0) [0|0] "" Vector__XXX
  SG_ EPS_WLMP   : 13|3@0+ (1,0) [0|0] "" Vector__XXX
  SG_ EPS_MINF   : 19|3@0+ (1,0) [0|0] "" Vector__XXX
  SG_ EPS_REMT   : 16|1@0+ (1,0) [0|0] "" Vector__XXX

BO_ 1570 BDB1S03: 8 Vector__XXX
  SG_ BDB03_ID   : 7|8@0+ (1,0) [0|0] "" Vector__XXX
  SG_ BDB03_IF   : 15|8@0+ (1,0) [0|0] "" Vector__XXX
  SG_ SULDCD   : 21|2@0+ (1,0) [0|0] "" Vector__XXX
  SG_ PANL   : 19|1@0+ (1,0) [0|0] "" Vector__XXX
  SG_ LED_HI_B   : 17|2@0+ (1,0) [0|0] "" Vector__XXX
  SG_ HEDH   : 30|1@0+ (1,0) [0|0] "" Vector__XXX
  SG_ HEDL   : 29|1@0+ (1,0) [0|0] "" Vector__XXX
  SG_ TAIL   : 28|1@0+ (1,0) [0|0] "" Vector__XXX
  SG_ FFOG   : 27|1@0+ (1,0) [0|0] "" Vector__XXX
  SG_ RFOG   : 26|1@0+ (1,0) [0|0] "" Vector__XXX
  SG_ SB_IND   : 39|2@0+ (1,0) [0|0] "" Vector__XXX
  SG_ SB_OK   : 37|1@0+ (1,0) [0|0] "" Vector__XXX
  SG_ RSRMID_R   : 47|2@0+ (1,0) [0|0] "" Vector__XXX
  SG_ RSR_PR   : 45|1@0+ (1,0) [0|0] "" Vector__XXX
  SG_ RSRON_ST   : 44|1@0+ (1,0) [0|0] "" Vector__XXX
  SG_ SRWARN   : 51|1@0+ (1,0) [0|0] "" Vector__XXX
  SG_ PWWARN   : 50|1@0+ (1,0) [0|0] "" Vector__XXX
  SG_ LTRBZ_R   : 49|1@0+ (1,0) [0|0] "" Vector__XXX
  SG_ DRPBZ_R   : 62|3@0+ (1,0) [0|0] "" Vector__XXX

BA_DEF_ "Manufacturer" STRING ;
BA_DEF_ "ILTxTimeout" INT 0 100000;
BA_DEF_ BU_ "ILUsed" ENUM "No","Yes";
BA_DEF_ BO_ "GenMsgSendType" ENUM "Cyclic","NotUsed","NotUsed","NotUsed","NotUsed","NotUsed","NotUsed","NotUsed","NoMsgSendType";
BA_DEF_ BO_ "GenMsgCycleTime" INT 2 50000;
BA_DEF_ BO_ "GenMsgDelayTime" INT 0 65535;
BA_DEF_ BO_ "GenMsgILSupport" ENUM "No","Yes";
BA_DEF_ BO_ "GenMsgTxConditionPlusBOn" ENUM "No","Yes";
BA_DEF_ BO_ "GenMsgTxConditionAccOn" ENUM "No","Yes";
BA_DEF_ BO_ "GenMsgTxConditionIg1On" ENUM "No","Yes";
BA_DEF_ BO_ "GenMsgTxConditionIg2On" ENUM "No","Yes";
BA_DEF_ BO_ "GenMsgTxConditionSpecialOn" ENUM "No","Yes";

BA_DEF_ SG_ "GenSigSendType" ENUM "Cyclic","OnWrite","NotUsed","OnChange","NotUsed","NotUsed","NotUsed","NoSigSendType";
BA_DEF_ SG_ "GenSigStartValue" FLOAT 0 100000000000;
BA_DEF_ SG_ "GenSigFuncType" ENUM "NoFunction","NotUsed","NotUsed","NotUsed","NotUsed","NotUsed","NotUsed","CHK";
BA_DEF_ BU_ "NodeLayerModules" STRING ;

BA_DEF_DEF_ "Manufacturer" "Toyota";
BA_DEF_DEF_ "ILTxTimeout" 400;
BA_DEF_DEF_ "ILUsed" "No";
BA_DEF_DEF_ "GenMsgSendType" "Cyclic";
BA_DEF_DEF_ "GenSigSendType" "NoSigSendType";
BA_DEF_DEF_ "GenMsgCycleTime" 100;
BA_DEF_DEF_ "GenMsgDelayTime" 0;
BA_DEF_DEF_ "GenMsgILSupport" "Yes";
BA_DEF_DEF_ "GenMsgTxConditionPlusBOn" "No";
BA_DEF_DEF_ "GenMsgTxConditionAccOn" "No";
BA_DEF_DEF_ "GenMsgTxConditionIg1On" "No";
BA_DEF_DEF_ "GenMsgTxConditionIg2On" "No";
BA_DEF_DEF_ "GenMsgTxConditionSpecialOn" "No";

BA_DEF_DEF_ "GenSigStartValue" 0;
BA_DEF_DEF_ "GenSigFuncType" "NoFunction";
BA_DEF_DEF_ "NodeLayerModules" "CANoeILNLToyota.dll";

BA_ "GenMsgCycleTime" BO_ 836 48;
BA_ "GenMsgTxConditionIg1On" BO_ 836 1;
BA_ "ILUsed" BU_ FCM 1;
BA_ "GenSigSendType" SG_ 836 DSS1GDRV 3;
BA_ "GenSigSendType" SG_ 836 PBATRGR 3;
BA_ "GenSigSendType" SG_ 836 VGRSTRGR 3;
BA_ "GenMsgCycleTime" BO_ 835 32;
BA_ "GenMsgTxConditionIg1On" BO_ 835 1;
BA_ "GenSigFuncType" SG_ 835 ACC03SUM 7;
BA_ "GenMsgCycleTime" BO_ 740 24;
BA_ "GenMsgTxConditionIg1On" BO_ 740 1;
BA_ "GenMsgCycleTime" BO_ 387 32;
BA_ "GenMsgTxConditionIg1On" BO_ 387 1;
BA_ "GenMsgCycleTime" BO_ 1572 1000;
BA_ "GenMsgTxConditionPlusBOn" BO_ 1572 1;
BA_ "GenMsgTxConditionAccOn" BO_ 1572 1;
BA_ "GenMsgTxConditionIg1On" BO_ 1572 1;
BA_ "ILUsed" BU_ CGW 1;
BA_ "GenSigStartValue" SG_ 1572 DEST_BDB 255;
BA_ "GenSigStartValue" SG_ 1572 C_CODE1 15;
BA_ "GenSigStartValue" SG_ 1572 C_CODE2 15;
BA_ "GenSigStartValue" SG_ 1572 C_CODE3 15;
BA_ "GenSigStartValue" SG_ 1572 STRG_WHL 3;
BA_ "GenSigStartValue" SG_ 1572 DEICER 1;
BA_ "GenSigStartValue" SG_ 1572 KEYPLATE 255;
BA_ "GenMsgCycleTime" BO_ 1014 1000;
BA_ "GenMsgTxConditionIg1On" BO_ 1014 1;
BA_ "ILUsed" BU_ BSR 1;
BA_ "GenSigSendType" SG_ 1014 BSD_STAT 3;
BA_ "GenSigStartValue" SG_ 1014 BSD_STAT 1;
BA_ "GenSigSendType" SG_ 1014 RCTA_DIR 3;
BA_ "GenSigSendType" SG_ 1014 BS4LDR 3;
BA_ "GenSigSendType" SG_ 1014 BS4LDL 3;
BA_ "GenSigSendType" SG_ 1014 BSD_SW 3;
BA_ "GenSigSendType" SG_ 1014 RCTA_EQ 3;
BA_ "GenSigSendType" SG_ 1014 RCTA_VOL 3;
BA_ "GenSigSendType" SG_ 1014 RCTADISP 3;
BA_ "GenSigSendType" SG_ 1014 CV4LDR 3;
BA_ "GenSigSendType" SG_ 1014 RCTA_SW 3;
BA_ "GenSigSendType" SG_ 1014 CV4LDL 3;
BA_ "GenSigSendType" SG_ 1014 BSD_BUZ 3;
BA_ "GenSigSendType" SG_ 1014 BSD_ILCR 3;
BA_ "GenSigSendType" SG_ 1014 BSD_ILV 3;
BA_ "GenSigSendType" SG_ 1014 BSD_ITCR 3;
BA_ "GenSigSendType" SG_ 1014 BSD_ITV 3;
BA_ "GenSigStartValue" SG_ 1014 BSD_ITV 2;
BA_ "GenSigSendType" SG_ 1014 BSD_OMIL 3;
BA_ "GenSigSendType" SG_ 1014 BSD_OMIR 3;
BA_ "GenSigSendType" SG_ 1014 RCTASTAT 3;
BA_ "GenSigStartValue" SG_ 1014 RCTASTAT 1;
BA_ "GenSigSendType" SG_ 1014 BUZSTAT 3;
BA_ "GenSigSendType" SG_ 1014 CAAICM 3;
BA_ "GenSigSendType" SG_ 1014 RCTALAMP 3;
BA_ "GenSigSendType" SG_ 1014 BSD_TTR 3;
BA_ "GenSigSendType" SG_ 1014 BSDINDI 3;
BA_ "GenSigSendType" SG_ 1014 RCTA_TTR 3;
BA_ "GenSigSendType" SG_ 1014 BSD_SWR 3;
BA_ "GenSigSendType" SG_ 1014 RCTA_SWR 3;
BA_ "GenSigSendType" SG_ 1014 RCTA_BUZ 3;
BA_ "GenSigSendType" SG_ 1014 RCTA_BCR 3;
BA_ "GenMsgCycleTime" BO_ 870 200;
BA_ "GenMsgDelayTime" BO_ 870 160;
BA_ "GenMsgTxConditionIg1On" BO_ 870 1;
BA_ "GenSigStartValue" SG_ 870 TGT_ETTC 63;
BA_ "GenSigSendType" SG_ 870 XREQALM 3;
BA_ "GenSigSendType" SG_ 870 XREQPBA 3;
BA_ "GenSigStartValue" SG_ 870 TGT_VGAP 255;
BA_ "GenSigStartValue" SG_ 870 TGT_DIST 127;
BA_ "GenSigStartValue" SG_ 870 TGT_NUMB 31;
BA_ "GenSigStartValue" SG_ 870 TGT_POSX 15;
BA_ "GenMsgCycleTime" BO_ 871 400;
BA_ "GenMsgDelayTime" BO_ 871 160;
BA_ "GenMsgTxConditionIg1On" BO_ 871 1;
BA_ "GenSigSendType" SG_ 871 LKADRTRG 3;
BA_ "GenSigSendType" SG_ 871 LKADRSHR 3;
BA_ "GenSigSendType" SG_ 871 LKADRSLK 3;
BA_ "GenSigSendType" SG_ 871 LKADRSLD 3;
BA_ "GenSigSendType" SG_ 871 LKADRCC 3;
BA_ "GenSigSendType" SG_ 871 LKADRTUR 3;
BA_ "GenSigSendType" SG_ 871 LKADRINV 3;
BA_ "GenMsgCycleTime" BO_ 830 200;
BA_ "GenMsgDelayTime" BO_ 830 160;
BA_ "GenMsgTxConditionIg1On" BO_ 830 1;
BA_ "GenSigStartValue" SG_ 830 TGT_ACCR 7;
BA_ "GenSigStartValue" SG_ 830 TGT_TTC 63;
BA_ "GenSigStartValue" SG_ 830 PCS_ALMM 3;
BA_ "GenMsgCycleTime" BO_ 1769 200;
BA_ "GenMsgTxConditionIg1On" BO_ 1769 1;
BA_ "GenMsgCycleTime" BO_ 1770 200;
BA_ "GenMsgTxConditionIg1On" BO_ 1770 1;
BA_ "GenMsgCycleTime" BO_ 643 32;
BA_ "GenMsgTxConditionIg1On" BO_ 643 1;
BA_ "GenSigSendType" SG_ 643 DSS1STAT 3;
BA_ "GenSigSendType" SG_ 643 DSS1FDRV 3;
BA_ "GenMsgCycleTime" BO_ 401 24;
BA_ "GenMsgTxConditionIg1On" BO_ 401 1;
BA_ "GenSigFuncType" SG_ 401 SM191 7;
BA_ "GenMsgCycleTime" BO_ 305 24;
BA_ "GenMsgTxConditionIg1On" BO_ 305 1;
BA_ "GenMsgCycleTime" BO_ 765 1000;
BA_ "GenMsgTxConditionIg1On" BO_ 765 1;
BA_ "GenSigFuncType" SG_ 765 SM2FD 7;
BA_ "GenMsgCycleTime" BO_ 881 200;
BA_ "GenMsgDelayTime" BO_ 881 160;
BA_ "GenMsgTxConditionIg1On" BO_ 881 1;
BA_ "GenSigSendType" SG_ 881 LTCDRTUR 3;
BA_ "GenSigSendType" SG_ 881 LTCDRTRG 3;
BA_ "GenSigSendType" SG_ 881 LTCDRSHR 3;
BA_ "GenSigSendType" SG_ 881 LTCDRSLK 3;
BA_ "GenSigSendType" SG_ 881 LTCDRCC 3;
BA_ "GenSigSendType" SG_ 881 LTCFLFLG 3;
BA_ "GenSigSendType" SG_ 881 LTCSPFLG 3;
BA_ "GenSigSendType" SG_ 881 LTCDRINV 3;
BA_ "GenMsgCycleTime" BO_ 1041 1000;
BA_ "GenMsgTxConditionIg1On" BO_ 1041 1;
BA_ "GenSigSendType" SG_ 1041 PCSINDI 3;
BA_ "GenSigSendType" SG_ 1041 PCSWM 3;
BA_ "GenSigSendType" SG_ 1041 PCSFCT 3;
BA_ "GenSigSendType" SG_ 1041 PCSTUCT 3;
BA_ "GenSigSendType" SG_ 1041 DS1LCCK 3;
BA_ "GenSigSendType" SG_ 1041 PBTUCT 3;
BA_ "GenSigSendType" SG_ 1041 PCSEXIST 3;
BA_ "GenSigSendType" SG_ 1041 PCSWDUCT 3;
BA_ "GenSigSendType" SG_ 1041 PCSMTBZ2 3;
BA_ "GenSigSendType" SG_ 1041 PCSDSRF 3;
BA_ "GenSigSendType" SG_ 1041 PCSTEMP 3;
BA_ "GenSigSendType" SG_ 1041 PCSDUST 3;
BA_ "GenSigSendType" SG_ 1041 PCSLCCK 3;
BA_ "GenSigSendType" SG_ 1041 PCTEMP2 3;
BA_ "GenSigSendType" SG_ 1041 PCSDUST2 3;
BA_ "GenSigSendType" SG_ 1041 PCSOFFS 3;
BA_ "GenSigSendType" SG_ 1041 PCSWDS 3;
BA_ "GenSigSendType" SG_ 1041 FRDADJ 3;
BA_ "GenSigSendType" SG_ 1041 TSS_TS 3;
BA_ "GenMsgCycleTime" BO_ 1042 1000;
BA_ "GenMsgDelayTime" BO_ 1042 160;
BA_ "GenMsgTxConditionIg1On" BO_ 1042 1;
BA_ "GenSigSendType" SG_ 1042 LKAINDI 3;
BA_ "GenSigSendType" SG_ 1042 LKAWLSL 3;
BA_ "GenSigSendType" SG_ 1042 LKAWLSR 3;
BA_ "GenSigSendType" SG_ 1042 LKAHS 3;
BA_ "GenSigSendType" SG_ 1042 LKAFCT 3;
BA_ "GenSigSendType" SG_ 1042 LKATUCT 3;
BA_ "GenSigSendType" SG_ 1042 LKACAMT 3;
BA_ "GenSigSendType" SG_ 1042 LKACB 3;
BA_ "GenSigSendType" SG_ 1042 LDWEXIST 3;
BA_ "GenSigSendType" SG_ 1042 LKAHFCT 3;
BA_ "GenSigSendType" SG_ 1042 LKASPCND 3;
BA_ "GenSigSendType" SG_ 1042 LKAMDCS 3;
BA_ "GenSigSendType" SG_ 1042 LKAWTCS 3;
BA_ "GenSigSendType" SG_ 1042 LKASAUT 3;
BA_ "GenSigSendType" SG_ 1042 LKAMDT 3;
BA_ "GenSigSendType" SG_ 1042 LTCCNFLV 3;
BA_ "GenSigSendType" SG_ 1042 FLWMD2 3;
BA_ "GenSigSendType" SG_ 1042 LDOFINDI 3;
BA_ "GenSigSendType" SG_ 1042 LDWBZ 3;
BA_ "GenSigSendType" SG_ 1042 LDAFCVB 3;
BA_ "GenSigSendType" SG_ 1042 SWSSENSD 3;
BA_ "GenSigSendType" SG_ 1042 SWSSWD 3;
BA_ "GenSigSendType" SG_ 1042 LDACD 3;
BA_ "GenSigSendType" SG_ 1042 SWSRAD 3;
BA_ "GenSigSendType" SG_ 1042 SWSBUZ 3;
BA_ "GenSigSendType" SG_ 1042 LKACTCD 3;
BA_ "GenMsgCycleTime" BO_ 295 16;
BA_ "GenMsgTxConditionIg2On" BO_ 295 1;
BA_ "GenSigFuncType" SG_ 295 EHVF02SM 7;
BA_ "GenMsgCycleTime" BO_ 278 24;
BA_ "GenMsgTxConditionIg1On" BO_ 278 1;
BA_ "GenMsgTxConditionIg2On" BO_ 278 1;
BA_ "GenMsgCycleTime" BO_ 375 32;
BA_ "GenMsgTxConditionIg1On" BO_ 375 1;
BA_ "GenMsgTxConditionIg2On" BO_ 375 1;
BA_ "GenSigStartValue" SG_ 375 RQBH 1;
BA_ "GenSigStartValue" SG_ 375 XPAIDLV 1;
BA_ "GenMsgCycleTime" BO_ 374 32;
BA_ "GenMsgTxConditionIg1On" BO_ 374 1;
BA_ "GenMsgTxConditionIg2On" BO_ 374 1;
BA_ "GenSigStartValue" SG_ 374 XPAIDL 1;
BA_ "GenSigFuncType" SG_ 374 SM176 7;
BA_ "GenMsgCycleTime" BO_ 252 1000;
BA_ "GenMsgTxConditionIg1On" BO_ 252 1;
BA_ "GenMsgTxConditionIg2On" BO_ 252 1;
BA_ "GenSigSendType" SG_ 252 B_TC 3;
BA_ "GenSigSendType" SG_ 252 B_ICC 3;
BA_ "GenSigSendType" SG_ 252 B_CCWG 3;
BA_ "GenSigSendType" SG_ 252 B_STPE 3;
BA_ "GenSigSendType" SG_ 252 CHAW_BZR 3;
BA_ "GenSigSendType" SG_ 252 CHAWID 3;
BA_ "GenSigSendType" SG_ 252 BOSLAMP 3;
BA_ "GenSigSendType" SG_ 252 BOSMINF 3;
BA_ "GenSigSendType" SG_ 252 CSRDRVRF 3;
BA_ "GenSigSendType" SG_ 252 GOSLAMP 3;
BA_ "GenSigSendType" SG_ 252 GOSMINF 3;
BA_ "GenMsgCycleTime" BO_ 921 1024;
BA_ "GenMsgTxConditionIg1On" BO_ 921 1;
BA_ "GenMsgTxConditionIg2On" BO_ 921 1;
BA_ "GenSigSendType" SG_ 921 ACCBZR 3;
BA_ "GenSigSendType" SG_ 921 B_SPU2 3;
BA_ "GenSigSendType" SG_ 921 ACASID1 3;
BA_ "GenSigSendType" SG_ 921 ACASID2 3;
BA_ "GenSigSendType" SG_ 921 RACMSDSP 3;
BA_ "GenSigSendType" SG_ 921 RACACOPR 3;
BA_ "GenSigSendType" SG_ 921 RACONDSP 3;
BA_ "GenSigSendType" SG_ 921 ASLBZR 3;
BA_ "GenSigSendType" SG_ 921 ACCOVSPD 3;
BA_ "GenSigSendType" SG_ 921 B_LSP2 3;
BA_ "GenSigSendType" SG_ 921 B_ASLSP2 3;
BA_ "GenSigSendType" SG_ 921 CACCTRN 3;
BA_ "GenSigSendType" SG_ 921 CACCINF 3;
BA_ "GenSigSendType" SG_ 921 CACCFR2 3;
BA_ "GenSigSendType" SG_ 921 CACCFR1 3;
BA_ "GenSigSendType" SG_ 921 CACCFLD 3;
BA_ "GenSigSendType" SG_ 921 CACCCM3 3;
BA_ "GenSigSendType" SG_ 921 CACCCM2 3;
BA_ "GenSigSendType" SG_ 921 CACCCM1 3;
BA_ "GenSigSendType" SG_ 921 ASLRNG 3;
BA_ "GenSigSendType" SG_ 921 RACCSTM2 3;
BA_ "GenSigSendType" SG_ 921 RACCSTM1 3;
BA_ "GenSigSendType" SG_ 921 RACEQPD 3;
BA_ "GenSigSendType" SG_ 921 RACID 3;
BA_ "GenSigSendType" SG_ 921 RACSPDOP 3;
BA_ "GenMsgCycleTime" BO_ 467 32;
BA_ "GenMsgTxConditionIg1On" BO_ 467 1;
BA_ "GenMsgTxConditionIg2On" BO_ 467 1;
BA_ "GenSigFuncType" SG_ 467 SM1D3 7;
BA_ "GenMsgCycleTime" BO_ 608 20;
BA_ "GenMsgTxConditionIg1On" BO_ 608 1;
BA_ "GenSigStartValue" SG_ 608 EST2F 1;
BA_ "GenSigStartValue" SG_ 608 IPSF 1;
BA_ "GenSigStartValue" SG_ 608 TRQSENSF 1;
BA_ "GenSigFuncType" SG_ 608 EPS01SUM 7;
BA_ "GenMsgCycleTime" BO_ 610 40;
BA_ "GenMsgTxConditionIg1On" BO_ 610 1;
BA_ "GenSigStartValue" SG_ 610 EPSTEMP1 255;
BA_ "GenSigStartValue" SG_ 610 EPSTEMP2 255;
BA_ "GenSigFuncType" SG_ 610 EPS02SUM 7;
BA_ "GenMsgCycleTime" BO_ 37 10;
BA_ "GenMsgTxConditionIg1On" BO_ 37 1;
BA_ "GenSigStartValue" SG_ 37 STDID 1;
BA_ "GenMsgCycleTime" BO_ 170 10;
BA_ "GenMsgTxConditionIg1On" BO_ 170 1;
BA_ "GenSigStartValue" SG_ 170 VXFR 6767;
BA_ "GenSigStartValue" SG_ 170 VXFL 6767;
BA_ "GenSigStartValue" SG_ 170 VXRR 6767;
BA_ "GenSigStartValue" SG_ 170 VXRL 6767;
BA_ "GenMsgCycleTime" BO_ 257 20;
BA_ "GenMsgTxConditionIg1On" BO_ 257 1;
BA_ "GenSigStartValue" SG_ 257 PMCS 1;
BA_ "GenSigFuncType" SG_ 257 SM101 7;
BA_ "GenMsgCycleTime" BO_ 417 50;
BA_ "GenMsgTxConditionIg1On" BO_ 417 1;
BA_ "GenSigStartValue" SG_ 417 FVSCM 1;
BA_ "GenSigStartValue" SG_ 417 CSRICM 1;
BA_ "GenSigFuncType" SG_ 417 SM1A1 7;
BA_ "GenMsgCycleTime" BO_ 315 30;
BA_ "GenMsgTxConditionIg1On" BO_ 315 1;
BA_ "GenSigFuncType" SG_ 315 SM13B 7;
BA_ "GenMsgCycleTime" BO_ 215 20;
BA_ "GenMsgTxConditionIg1On" BO_ 215 1;
BA_ "GenSigStartValue" SG_ 215 SP1S 1;
BA_ "GenMsgCycleTime" BO_ 264 20;
BA_ "GenMsgTxConditionIg1On" BO_ 264 1;
BA_ "GenSigFuncType" SG_ 264 SM108 7;
BA_ "GenMsgCycleTime" BO_ 1056 1000;
BA_ "GenMsgTxConditionIg1On" BO_ 1056 1;
BA_ "GenSigStartValue" SG_ 1056 GLZS 1;
BA_ "GenSigStartValue" SG_ 1056 YRZS 1;
BA_ "GenSigFuncType" SG_ 1056 VSC08SUM 7;
